# ASR6601 register map
Vendor: ASR Microelectronics; Series: ASR6601; File version: 1
CPU: CM4 r0p1, little endian, no MPU, FPU, 3 interrupt priority bits
Registers are 32-bit, read-write, reset 0x0 unless marked. A register's access mark holds for its fields unless they carry their own. Offsets are from the block's base; [hi:lo] are bit positions; {n}, {i} and the like mark numbered series; 'fields as' and 'values as' point back to an identical list.

## UART0 — Universal Asynchronous Receiver/Transmitter Controller
Base 0x40003000
Same registers: UART1 0x40004000, UART2 0x40010000, UART3 0x40011000
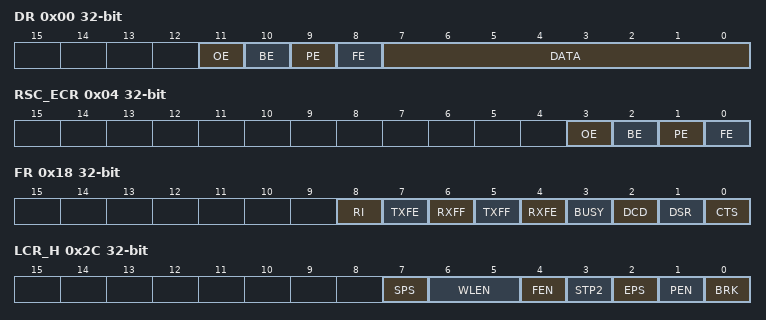
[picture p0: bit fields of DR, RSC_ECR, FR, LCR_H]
0x00 DR — Data register
  [11] OE — Overrun error
  [10] BE — Break error
  [9] PE — Parity error
  [8] FE — Framing error
  [7:0] DATA — Data character
0x04 RSC_ECR — Receive status and error clear register
  [3] OE — Overrun error
  [2] BE — Break error
  [1] PE — Parity error
  [0] FE — Framing error
0x18 FR ro — Flag register
  [8] RI — Ring indicator
    0=CLR_FLAG (RI is high); 1=SET_FLAG (RI is low)
  [7] TXFE — Transmit FIFO empty
    0=CLR_FLAG (Transmit FIFO is not empty); 1=SET_FLAG (Transmit FIFO is empty)
  [6] RXFF — Receive FIFO full
    0=CLR_FLAG (Receive FIFO not full); 1=SET_FLAG (Receive FIFO full)
  [5] TXFF — Transmit FIFO full
    0=CLR_FLAG (Transmit FIFO not full); 1=SET_FLAG (Transmit FIFO full)
  [4] RXFE — Receive FIFO empty
    0=CLR_FLAG (Receive FIFO is not empty); 1=SET_FLAG (Receive FIFO is empty)
  [3] BUSY
    0=CLR_FLAG (Not busy); 1=SET_FLAG (Busy)
  [2] DCD — Data carrier detect
    0=CLR_FLAG (DCD is high); 1=SET_FLAG (DCD is low)
  [1] DSR — Data set ready
    0=CLR_FLAG (DSR is high); 1=SET_FLAG (DSR is low)
  [0] CTS — Clear to send
    0=CLR_FLAG (CTS is high); 1=SET_FLAG (CTS is low)
0x20 ILPR — IRDA low power counter register
  [7:0] ILPDVSR — 8-bit low-power divisor value
0x24 IBRD — Integer baud rate register
  [15:0] BAUD_DIVINT — The integer baud rate divisor
0x28 FBRD — Fractional baud rate register
  [5:0] BAUD_DIVFRAC — The fractional baud rate divisor
0x2C LCR_H — Line control register
  [7] SPS — Stick parity select
    0=DIS (Stick parity disable); 1=EN (Stick parity enable)
  [6:5] WLEN — Data width
    {v}={v+5} bytes (v=0..3)
  [4] FEN — Enable FIFOs
    0=DIS (FIFOs disable); 1=EN (FIFOs enable)
  [3] STP2 — Stop bits number
    0=1 stop bit; 1=2 stop bits
  [2] EPS — Even parity select
    0=DIS (Odd parity); 1=EN (Even parity)
  [1] PEN — Parity enable
    0=DIS (Parity bit disable); 1=EN (Parity bit enable)
  [0] BRK — Send break
    0=DIS (Normal use); 1=EN (Send break)
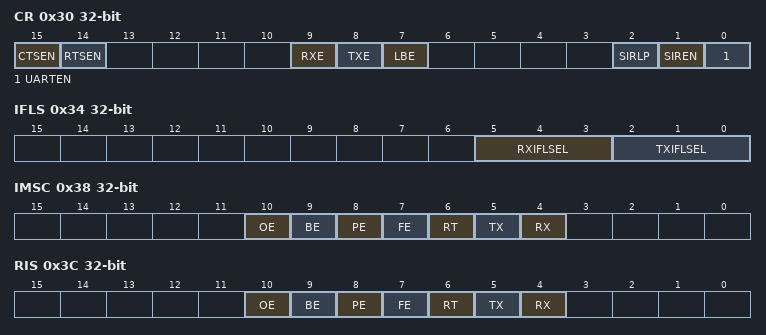
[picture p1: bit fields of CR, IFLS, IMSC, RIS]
0x30 CR — Control register
  [15] CTSEN — CTS hardware flow control enable
    0=DIS (CTS disable); 1=EN (CTS enable)
  [14] RTSEN — RTS hardware flow control enable
    0=DIS (RTS disable); 1=EN (RTS enable)
  [9] RXE — Receive enable
    0=DIS (Receive disable); 1=EN (Receive enable)
  [8] TXE — Transmit enable
    0=DIS (Transmit disable); 1=EN (Transmit enable)
  [7] LBE — Loopback enable
    0=DIS (Loopback disable); 1=EN (Loopback enable)
  [2] SIRLP — SIR low-power IrDA mode
    0=DIS (SIR low-power IrDA mode disable); 1=EN (SIR low-power IrDA mode enable)
  [1] SIREN — SIR enable
    0=DIS (SIR disable); 1=EN (SIR enable)
  [0] UARTEN — UART enable
    0=DIS (UART disable); 1=EN (UART enable)
0x34 IFLS — Interrupt fifo level select register
  [5:3] RXIFLSEL — Receive interrupt FIFO level select
    0=1_8; 1=1_4; 2=1_2; 3=3_4; 4=7_8
  [2:0] TXIFLSEL — Transmit interrupt FIFO level select
    0=1_8; 1=1_4; 2=1_2; 3=3_4; 4=7_8
0x38 IMSC — Interrupt mask set/clear register
  [10] OE — Overrun error interrupt mask
    0=CLR_FLAG (Overrun error interrupt is masked); 1=SET_FLAG (Overrun error interrupt is not masked)
  [9] BE — Break error interrupt mask
    0=CLR_FLAG (Break error interrupt is masked); 1=SET_FLAG (Break error interrupt is not masked)
  [8] PE — Parity error interrupt mask
    0=CLR_FLAG (Parity error interrupt is masked); 1=SET_FLAG (Parity error interrupt is not masked)
  [7] FE — Framing error interrupt mask
    0=CLR_FLAG (Framing error interrupt is masked); 1=SET_FLAG (Framing error interrupt is not masked)
  [6] RT — Receive timeout interrupt mask
    0=CLR_FLAG (Receive timeout interrupt is masked); 1=SET_FLAG (Receive timeout interrupt is not masked)
  [5] TX — Transmit interrupt mask
    0=CLR_FLAG (Transmit interrupt mask is masked); 1=SET_FLAG (Transmit interrupt mask is not masked)
  [4] RX — Receive interrupt mask
    0=CLR_FLAG (Receive interrupt mask is masked); 1=SET_FLAG (Receive interrupt mask is not masked)
0x3C RIS ro — Raw interrupt status register
  [all] fields
    0=CLR_FLAG (Interrupt not triggered); 1=SET_FLAG (Interrupt triggered)
  [10] OE — Overrun error interrupt status
  [9] BE — Break error interrupt status
  [8] PE — Parity error interrupt status
  [7] FE — Framing error interrupt status
  [6] RT — Receive timeout interrupt status
  [5] TX — Transmit interrupt status
  [4] RX — Receive interrupt status
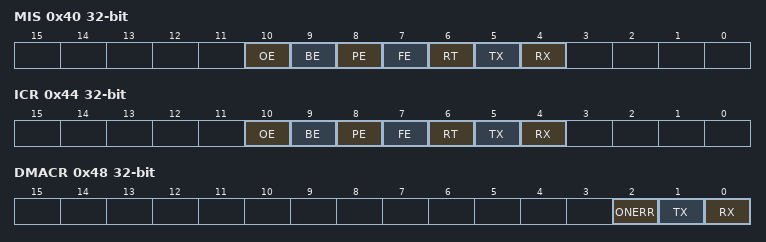
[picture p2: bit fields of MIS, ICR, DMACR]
0x40 MIS ro — Masked interrupt status register
  [all] fields
    values as the fields of RIS
  [10] OE — Overrun error masked interrupt status
  [9] BE — Break error masked interrupt status
  [8] PE — Parity error masked interrupt status
  [7] FE — Framing error masked interrupt status
  [6] RT — Receive timeout masked interrupt status
  [5] TX — Transmit masked interrupt status
  [4] RX — Receive masked interrupt status
0x44 ICR wo — Interrupt clear register
  [all] fields
    0=CLR_FLAG (No effect); 1=SET_FLAG (Clear interrupt)
  [10] OE — Overrun error interrupt clear
  [9] BE — Break error interrupt clear
  [8] PE — Parity error interrupt clear
  [7] FE — Frame error interrupt clear
  [6] RT — Receive timeout interrupt clear
  [5] TX — Transmit interrupt clear
  [4] RX — Receive interrupt clear
0x48 DMACR — DMA control register
  [2] ONERR — DMA on error
    0=DIS (DMA on error disable); 1=EN (DMA on error enable)
  [1] TX — Transmit DMA enable
    0=DIS (Transmit DMA disable); 1=EN (Transmit DMA enable)
  [0] RX — Receive DMA enable
    0=DIS (Receive DMA disable); 1=EN (Receive DMA enable)
